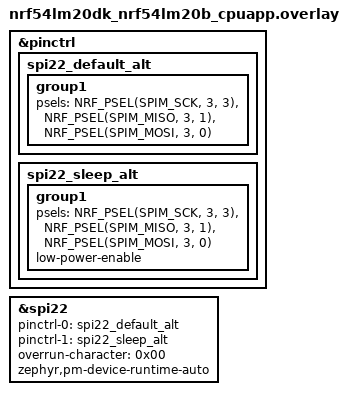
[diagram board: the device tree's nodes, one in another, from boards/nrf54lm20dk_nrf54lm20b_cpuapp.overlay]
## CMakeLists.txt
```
cmake_minimum_required(VERSION 3.20.0)
find_package(Zephyr REQUIRED HINTS $ENV{ZEPHYR_BASE})
project(spi_master)

target_sources(app PRIVATE src/main.c)
```

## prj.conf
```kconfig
CONFIG_SPI=y
CONFIG_PRINTK=y
CONFIG_GPIO=y
```

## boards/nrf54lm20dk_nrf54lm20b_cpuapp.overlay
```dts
/* SPI master using spi22 on PORT3 pins (verified working between boards) */

&pinctrl {
	spi22_default_alt: spi22_default_alt {
		group1 {
			psels = <NRF_PSEL(SPIM_SCK, 3, 3)>,
				<NRF_PSEL(SPIM_MISO, 3, 1)>,
				<NRF_PSEL(SPIM_MOSI, 3, 0)>;
		};
	};

	spi22_sleep_alt: spi22_sleep_alt {
		group1 {
			psels = <NRF_PSEL(SPIM_SCK, 3, 3)>,
				<NRF_PSEL(SPIM_MISO, 3, 1)>,
				<NRF_PSEL(SPIM_MOSI, 3, 0)>;
			low-power-enable;
		};
	};
};

&spi22 {
	status = "okay";
	pinctrl-0 = <&spi22_default_alt>;
	pinctrl-1 = <&spi22_sleep_alt>;
	pinctrl-names = "default", "sleep";
	overrun-character = <0x00>;
	/* CS is driven manually as a plain GPIO in main.c (P3.02),
	 * so we intentionally do NOT declare cs-gpios here.
	 */
	zephyr,pm-device-runtime-auto;
};
```

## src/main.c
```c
/*
 * SPI Master — streams an incrementing SEQUENCE NUMBER over the Intan-style link.
 *
 * This is the data-integrity / latency test: the master sends 0,1,2,3,... as
 * 16-bit words. The slave prints each value it receives; a host-side Python
 * script graphs the sequence. Because the numbers should increase by exactly 1
 * each step, any gap = dropped data, and arrival timing = streaming delay.
 *
 * Same physical protocol as the real Intan link (16-bit words, MSB first,
 * mode 0, one CS pulse per word) — only the payload is a counter instead of a
 * CONVERT command, so this genuinely exercises the link we'll use.
 */

#include <zephyr/kernel.h>
#include <zephyr/device.h>
#include <zephyr/drivers/gpio.h>
#include <zephyr/drivers/spi.h>

#define SPI_NODE      DT_NODELABEL(spi22)
#define CS_PIN        2       /* P3.02, driven manually */
#define SEND_PERIOD_US 10     /* push it: effective rate is capped ~8 kHz by the
                              * per-word CS busy-waits in intan_send (Stage B trims those) */

static const struct device *spi_dev = DEVICE_DT_GET(SPI_NODE);
static const struct device *gpio3   = DEVICE_DT_GET(DT_NODELABEL(gpio3));

static struct spi_config spi_cfg = {
	.frequency = 1000000,     /* well under Intan's 24 MHz max */
	.operation = SPI_WORD_SET(8) | SPI_TRANSFER_MSB | SPI_OP_MODE_MASTER, /* mode 0 */
	.slave = 0,
	/* no .cs — we frame the transaction manually below */
};

/* Send one 16-bit word inside a single manual-CS frame (Intan-style). */
static void intan_send(uint16_t word)
{
	uint8_t tx[2] = { word >> 8, word & 0xFF };   /* MSB first */
	uint8_t rx[2] = { 0, 0 };

	struct spi_buf tx_buf = { .buf = tx, .len = 2 };
	struct spi_buf_set tx_set = { .buffers = &tx_buf, .count = 1 };
	struct spi_buf rx_buf = { .buf = rx, .len = 2 };
	struct spi_buf_set rx_set = { .buffers = &rx_buf, .count = 1 };

	gpio_pin_set(gpio3, CS_PIN, 0);   /* assert CS low */
	k_busy_wait(50);                  /* 50us setup — let the slave's SPIS arm */
	spi_transceive(spi_dev, &spi_cfg, &tx_set, &rx_set);
	k_busy_wait(50);                  /* 50us hold */
	gpio_pin_set(gpio3, CS_PIN, 1);   /* deassert CS high */
}

int main(void)
{
	printk("=== SPI Master - streaming sequence numbers ===\n");

	if (!device_is_ready(spi_dev) || !device_is_ready(gpio3)) {
		printk("SPI or GPIO not ready\n");
		return 0;
	}

	gpio_pin_configure(gpio3, CS_PIN, GPIO_OUTPUT_HIGH);   /* CS idle high */

	uint16_t seq = 0;

	while (1) {
		intan_send(seq);   /* send the counter; wraps at 65536 */
		seq++;
		k_usleep(SEND_PERIOD_US);
	}

	return 0;
}
```
